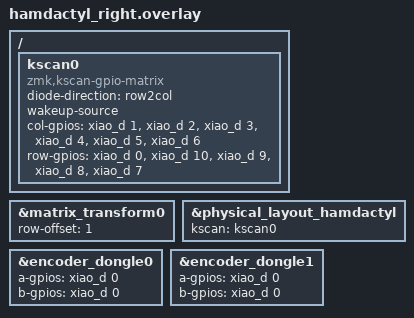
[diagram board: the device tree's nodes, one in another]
#include "hamdactyl.dtsi"

/ {
    kscan0: kscan0 {
        compatible = "zmk,kscan-gpio-matrix";
        diode-direction = "row2col";
        wakeup-source;

        col-gpios
            = <&xiao_d 1 (GPIO_ACTIVE_HIGH | GPIO_PULL_DOWN)>
            , <&xiao_d 2 (GPIO_ACTIVE_HIGH | GPIO_PULL_DOWN)>
            , <&xiao_d 3 (GPIO_ACTIVE_HIGH | GPIO_PULL_DOWN)>
            , <&xiao_d 4 (GPIO_ACTIVE_HIGH | GPIO_PULL_DOWN)>
            , <&xiao_d 5 (GPIO_ACTIVE_HIGH | GPIO_PULL_DOWN)>
            , <&xiao_d 6 (GPIO_ACTIVE_HIGH | GPIO_PULL_DOWN)>
            ;

        row-gpios
            = <&xiao_d 0 GPIO_ACTIVE_HIGH>
            , <&xiao_d 10 GPIO_ACTIVE_HIGH>
            , <&xiao_d 9 GPIO_ACTIVE_HIGH>
            , <&xiao_d 8 GPIO_ACTIVE_HIGH>
            , <&xiao_d 7 GPIO_ACTIVE_HIGH>
            ;
    };
};

&matrix_transform0 {
    row-offset = <1>;
};

&physical_layout_hamdactyl {
    kscan = <&kscan0>;
};

// Assigning dummy pins to other part's encoders
// just to satisfy the devicetree requirements.
// No code will be compiled for these disabled encoders.
&encoder_dongle0 {
    a-gpios = <&xiao_d 0 (GPIO_ACTIVE_HIGH | GPIO_PULL_UP)>;
    b-gpios = <&xiao_d 0 (GPIO_ACTIVE_HIGH | GPIO_PULL_UP)>;
};
&encoder_dongle1 {
    a-gpios = <&xiao_d 0 (GPIO_ACTIVE_HIGH | GPIO_PULL_UP)>;
    b-gpios = <&xiao_d 0 (GPIO_ACTIVE_HIGH | GPIO_PULL_UP)>;
};

